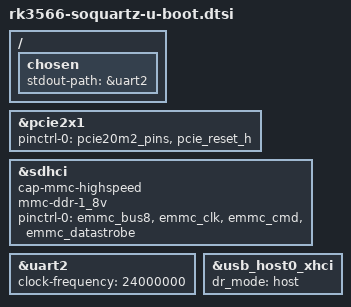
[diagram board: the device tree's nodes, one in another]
// SPDX-License-Identifier: GPL-2.0+

#include "rk356x-u-boot.dtsi"

/ {
	chosen {
		stdout-path = &uart2;
	};
};

&pcie2x1 {
	pinctrl-0 = <&pcie20m2_pins &pcie_reset_h>;
};

&sdhci {
	cap-mmc-highspeed;
	mmc-ddr-1_8v;
	pinctrl-names = "default";
	pinctrl-0 = <&emmc_bus8 &emmc_clk &emmc_cmd &emmc_datastrobe>;
};

&uart2 {
	bootph-all;
	clock-frequency = <24000000>;
	status = "okay";
};

&usb_host0_xhci {
	dr_mode = "host";
};
